# CY8C5888LTI_LP097 register map
File version: 0.1
CY8C58LP
Registers are 8-bit, read-write, no defined reset value unless marked. A register's access mark holds for its fields unless they carry their own. Offsets are from the block's base; lines under a group give offsets from that group; [hi:lo] are bit positions; {n}, {i} and the like mark numbered series; 'fields as' and 'values as' point back to an identical list; <NAME> marks a mode.

## Memory map
0x00000000 RTC_SEC_COUNTER
0x00000000 SEC_COUNTER
0x00000000 MILLIS_CTR_CAPTSEL
0x00000000 BUTTONPRESS_REG
0x00000000 MILLIS_COUNTER
0x00000000 I2C
0x00000000 USBUART — USBFS
0x00000000 CTR_SYNC_EN

## RTC_SEC_COUNTER
Base 0x00000000
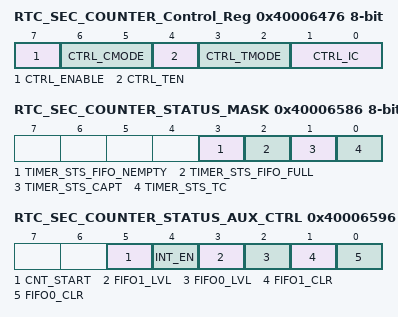
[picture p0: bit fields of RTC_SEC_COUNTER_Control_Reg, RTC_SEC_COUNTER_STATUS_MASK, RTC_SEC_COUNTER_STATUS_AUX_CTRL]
0x40006476 RTC_SEC_COUNTER_Control_Reg — UDB Control Register - Assigned Control Register Value
  [7] CTRL_ENABLE — Enable the Timer
  [6:5] CTRL_CMODE — Capture Mode
  [4] CTRL_TEN — Trigger Enable Bit
  [3:2] CTRL_TMODE — Trigger Mode
  [1:0] CTRL_IC — Interrupt Count
0x40006505 RTC_SEC_COUNTER_COUNTER 16-bit — UDB.A0 - Current Down Counter Value
0x40006525 RTC_SEC_COUNTER_PERIOD 16-bit — UDB.D0 - Assigned Period
0x40006586 RTC_SEC_COUNTER_STATUS_MASK — UDB Status bits Interrupt Mask Enable Register
  [3] TIMER_STS_FIFO_NEMPTY ro — FIFO Empty status
  [2] TIMER_STS_FIFO_FULL ro — FIFO Full Status
  [1] TIMER_STS_CAPT ro — Enables the Interrupt on Capture
  [0] TIMER_STS_TC ro — Enables the Interrupt on TC
0x40006596 RTC_SEC_COUNTER_STATUS_AUX_CTRL — UDB Auxilliary Control Register
  [5] CNT_START — FIFO0 clear
    0=E_CNT_START0 (Disable counter); 1=E_CNT_START1 (Enable counter)
  [4] INT_EN
    0=E_INT_EN0 (Interrupt disabled); 1=E_INT_EN1 (Interrupt enabled)
  [3] FIFO1_LVL — FIFO level
    0=E_FIFO_LVL_0 (FIFO LVL: input mode: FIFO not full; output mode: FIFO not empty); 1=E_FIFO_LVL_1 (FIFO LVL: input mode: FIFO at least 1/2 empty; output mode: FIFO at least 1/2 full)
  [2] FIFO0_LVL — FIFO level
    values as FIFO1_LVL
  [1] FIFO1_CLR — FIFO1 clear
    0=E_FIFO_CLR_0 (Normal FIFO operation); 1=E_FIFO_CLR_1 (Clear FIFO state)
  [0] FIFO0_CLR — FIFO0 clear
    values as FIFO1_CLR

## SEC_COUNTER
Base 0x00000000
0x40006507 SEC_COUNTER_COUNTER — UDB.A0 - Current Counter Value
0x40006527 SEC_COUNTER_PERIOD — UDB.D0 - Assigned Period
0x40006537 SEC_COUNTER_COMPARE — UDB.D1 - Assigned Compare Value
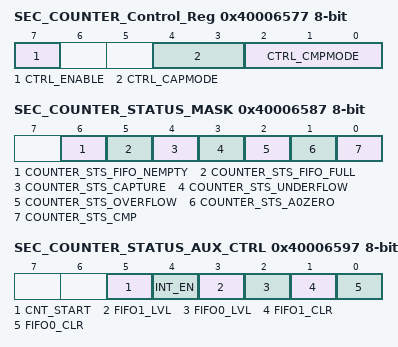
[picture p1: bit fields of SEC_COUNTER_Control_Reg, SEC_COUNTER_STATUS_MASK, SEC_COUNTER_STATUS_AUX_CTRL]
0x40006577 SEC_COUNTER_Control_Reg — UDB Control Register - Assigned Control Register Value
  [7] CTRL_ENABLE — Enable Counter
  [4:3] CTRL_CAPMODE — Capture mode
  [2:0] CTRL_CMPMODE — Compare mode
0x40006587 SEC_COUNTER_STATUS_MASK — UDB Status bits Interrupt Mask Enable Register
  [6] COUNTER_STS_FIFO_NEMPTY — FIFO Not Empty Status
  [5] COUNTER_STS_FIFO_FULL — FIFO Full Status
  [4] COUNTER_STS_CAPTURE — Capture Status
  [3] COUNTER_STS_UNDERFLOW — Underflow status
  [2] COUNTER_STS_OVERFLOW — Overflow status
  [1] COUNTER_STS_A0ZERO — A0 Zero ouput status
  [0] COUNTER_STS_CMP — Compare output status
0x40006597 SEC_COUNTER_STATUS_AUX_CTRL — UDB Auxilliary Control Register
  [5] CNT_START — FIFO0 clear
    0=E_CNT_START0 (Disable counter); 1=E_CNT_START1 (Enable counter)
  [4] INT_EN
    0=E_INT_EN0 (Interrupt disabled); 1=E_INT_EN1 (Interrupt enabled)
  [3] FIFO1_LVL — FIFO level
    0=E_FIFO_LVL_0 (FIFO LVL: input mode: FIFO not full; output mode: FIFO not empty); 1=E_FIFO_LVL_1 (FIFO LVL: input mode: FIFO at least 1/2 empty; output mode: FIFO at least 1/2 full)
  [2] FIFO0_LVL — FIFO level
    values as FIFO1_LVL
  [1] FIFO1_CLR — FIFO1 clear
    0=E_FIFO_CLR_0 (Normal FIFO operation); 1=E_FIFO_CLR_1 (Clear FIFO state)
  [0] FIFO0_CLR — FIFO0 clear
    values as FIFO1_CLR

## MILLIS_CTR_CAPTSEL
Base 0x00000000
0x40006477 MILLIS_CTR_CAPTSEL_CONTROL_REG

## BUTTONPRESS_REG
Base 0x00000000
0x40006565 BUTTONPRESS_REG_STATUS_REG
0x40006585 BUTTONPRESS_REG_MASK_REG
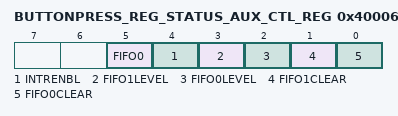
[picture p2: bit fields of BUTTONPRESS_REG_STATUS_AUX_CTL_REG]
0x40006595 BUTTONPRESS_REG_STATUS_AUX_CTL_REG
  [5] FIFO0 — FIFO0 clear
    1=ENABLED (Enable counter); 0=DISABLED (Disable counter)
  [4] INTRENBL — Enables or disables the Interrupt
    1=ENABLED (Interrupt enabled); 0=DISABLED (Interrupt disabled)
  [3] FIFO1LEVEL — FIFO level
    1=ENABLED (FIFO LVL: input mode: FIFO at least 1/2 empty; output mode: FIFO at least 1/2 full); 0=DISABLED (FIFO LVL: input mode: FIFO not full; output mode: FIFO not empty)
  [2] FIFO0LEVEL — FIFO level
    values as FIFO1LEVEL
  [1] FIFO1CLEAR — FIFO clear
    1=ENABLED (Clear FIFO state); 0=DISABLED (Normal FIFO operation)
  [0] FIFO0CLEAR — FIFO clear
    values as FIFO1CLEAR
